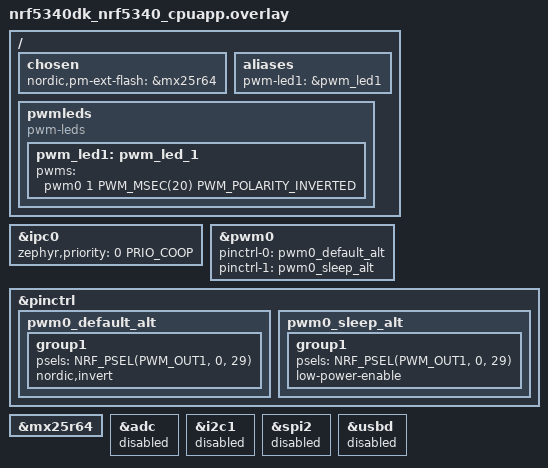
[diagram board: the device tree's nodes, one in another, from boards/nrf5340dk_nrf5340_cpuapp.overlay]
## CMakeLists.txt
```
#
#    Copyright (c) 2020 Project CHIP Authors
#
#    Licensed under the Apache License, Version 2.0 (the "License");
#    you may not use this file except in compliance with the License.
#    You may obtain a copy of the License at
#
#        http://www.apache.org/licenses/LICENSE-2.0
#
#    Unless required by applicable law or agreed to in writing, software
#    distributed under the License is distributed on an "AS IS" BASIS,
#    WITHOUT WARRANTIES OR CONDITIONS OF ANY KIND, either express or implied.
#    See the License for the specific language governing permissions and
#    limitations under the License.
#
cmake_minimum_required(VERSION 3.20)

get_filename_component(CHIP_ROOT ${CMAKE_CURRENT_SOURCE_DIR}/third_party/connectedhomeip REALPATH)
get_filename_component(NRFCONNECT_COMMON ${CHIP_ROOT}/examples/platform/nrfconnect REALPATH)
get_filename_component(LIGHTING_COMMON ${CHIP_ROOT}/examples/lighting-app/lighting-common REALPATH)
get_filename_component(GEN_DIR ${CHIP_ROOT}/zzz_generated/ REALPATH)

include(${CHIP_ROOT}/config/nrfconnect/app/check-nrfconnect-version.cmake)

list(APPEND ZEPHYR_EXTRA_MODULES ${CHIP_ROOT}/config/nrfconnect/chip-module)
find_package(Zephyr HINTS $ENV{ZEPHYR_BASE})

project(chip-nrfconnect-lighting-example)

include(${CHIP_ROOT}/config/nrfconnect/app/check-sysbuild-use.cmake)
include(${CHIP_ROOT}/config/nrfconnect/app/enable-gnu-std.cmake)
include(${CHIP_ROOT}/config/nrfconnect/app/flashing.cmake)
include(${CHIP_ROOT}/src/app/chip_data_model.cmake)

# -Wmaybe-uninitialized has too many false positives, including on std::optional
# and chip::Optional.  Make it nonfatal.
#
# See https://gcc.gnu.org/bugzilla/show_bug.cgi?id=80635
target_compile_options(app PRIVATE -Werror -Wno-error=maybe-uninitialized)

target_include_directories(app PRIVATE
                           main/include
                           ${LIGHTING_COMMON}
                           ${GEN_DIR}
                           ${GEN_DIR}/app-common
                           ${GEN_DIR}/lighting-app
                           ${NRFCONNECT_COMMON}/util/include
                           ${NRFCONNECT_COMMON}/app/include)

target_sources(app PRIVATE
               main/AppTask.cpp
               main/main.cpp
               main/ZclCallbacks.cpp
               ${CHIP_ROOT}/src/app/persistence/DeferredAttributePersistenceProvider.cpp
               ${NRFCONNECT_COMMON}/util/LEDWidget.cpp
               ${NRFCONNECT_COMMON}/util/PWMDevice.cpp)

chip_configure_data_model(app
    ZAP_FILE ${CMAKE_CURRENT_SOURCE_DIR}/../lighting-common/lighting-app.zap
)

if(CONFIG_CHIP_OTA_REQUESTOR OR CONFIG_MCUMGR_TRANSPORT_BT)
    target_sources(app PRIVATE ${NRFCONNECT_COMMON}/util/OTAUtil.cpp)
endif()

if(CONFIG_MCUMGR_TRANSPORT_BT)
    zephyr_library_link_libraries(MCUBOOT_BOOTUTIL)
    target_sources(app PRIVATE ${NRFCONNECT_COMMON}/util/DFUOverSMP.cpp)
endif()

if (CONFIG_SHELL AND BOARD STREQUAL "nrf52840dongle_nrf52840")
  target_sources(app PRIVATE ${NRFCONNECT_COMMON}/util/DFUTrigger.cpp)
endif()

if (CONFIG_CHIP_PW_RPC)

# Make all targets created below depend on zephyr_interface to inherit MCU-related compilation flags
link_libraries($<BUILD_INTERFACE:zephyr_interface>)

set(PIGWEED_ROOT "${CHIP_ROOT}/third_party/pigweed/repo")
include(${PIGWEED_ROOT}/pw_build/pigweed.cmake)
include(${PIGWEED_ROOT}/pw_protobuf_compiler/proto.cmake)

pw_set_module_config(pw_rpc_CONFIG pw_rpc.disable_global_mutex_config)
pw_set_backend(pw_log pw_log_basic)
pw_set_backend(pw_assert.check pw_assert_log.check_backend)
pw_set_backend(pw_assert.assert pw_assert.assert_compatibility_backend)
pw_set_backend(pw_sys_io pw_sys_io.nrfconnect)
set(dir_pw_third_party_nanopb "${CHIP_ROOT}/third_party/nanopb/repo" CACHE STRING "" FORCE)

add_subdirectory(third_party/connectedhomeip/examples/platform/nrfconnect/pw_sys_io)
add_subdirectory(third_party/connectedhomeip/third_party/nanopb/repo)
add_subdirectory(third_party/connectedhomeip/third_party/pigweed/repo)

pw_proto_library(attributes_service
  SOURCES
    ${CHIP_ROOT}/examples/common/pigweed/protos/attributes_service.proto
  INPUTS
    ${CHIP_ROOT}/examples/common/pigweed/protos/attributes_service.options
  PREFIX
    attributes_service
  STRIP_PREFIX
    ${CHIP_ROOT}/examples/common/pigweed/protos
  DEPS
    pw_protobuf.common_proto
)

pw_proto_library(button_service
  SOURCES
    ${CHIP_ROOT}/examples/common/pigweed/protos/button_service.proto
  PREFIX
    button_service
  STRIP_PREFIX
    ${CHIP_ROOT}/examples/common/pigweed/protos
  DEPS
    pw_protobuf.common_proto
)

pw_proto_library(descriptor_service
  SOURCES
    ${CHIP_ROOT}/examples/common/pigweed/protos/descriptor_service.proto
  PREFIX
    descriptor_service
  STRIP_PREFIX
    ${CHIP_ROOT}/examples/common/pigweed/protos
  DEPS
    pw_protobuf.common_proto
)

pw_proto_library(device_service
  SOURCES
    ${CHIP_ROOT}/examples/common/pigweed/protos/device_service.proto
  INPUTS
    ${CHIP_ROOT}/examples/common/pigweed/protos/device_service.options
  PREFIX
    device_service
  STRIP_PREFIX
    ${CHIP_ROOT}/examples/common/pigweed/protos
  DEPS
    pw_protobuf.common_proto
)

pw_proto_library(lighting_service
  SOURCES
    ${CHIP_ROOT}/examples/common/pigweed/protos/lighting_service.proto
  STRIP_PREFIX
    ${CHIP_ROOT}/examples/common/pigweed/protos
  PREFIX
    lighting_service
  DEPS
    pw_protobuf.common_proto
)

pw_proto_library(ot_cli_service
  SOURCES
    ${CHIP_ROOT}/examples/common/pigweed/protos/ot_cli_service.proto
  INPUTS
    ${CHIP_ROOT}/examples/common/pigweed/protos/ot_cli_service.options
  STRIP_PREFIX
    ${CHIP_ROOT}/examples/common/pigweed/protos
  PREFIX
    ot_cli_service
  DEPS
    pw_protobuf.common_proto
)

pw_proto_library(thread_service
  SOURCES
    ${CHIP_ROOT}/examples/common/pigweed/protos/thread_service.proto
  INPUTS
    ${CHIP_ROOT}/examples/common/pigweed/protos/thread_service.options
  STRIP_PREFIX
    ${CHIP_ROOT}/examples/common/pigweed/protos
  PREFIX
    thread_service
  DEPS
    pw_protobuf.common_proto
)

target_sources(app PRIVATE
  ../../common/pigweed/RpcService.cpp
  ../../common/pigweed/nrfconnect/PigweedLoggerMutex.cpp
  ${NRFCONNECT_COMMON}/Rpc.cpp
  ${NRFCONNECT_COMMON}/util/PigweedLogger.cpp
)

target_include_directories(app PRIVATE
  ${CHIP_ROOT}/src/lib/support
  ${CHIP_ROOT}/src/system
  ${NRFCONNECT_COMMON}
  ../../common
  ../../common/pigweed
  ../../common/pigweed/nrfconnect)

target_compile_options(app PRIVATE
                       "-DPW_RPC_ATTRIBUTE_SERVICE=1"
                       "-DPW_RPC_BUTTON_SERVICE=1"
                       "-DPW_RPC_DESCRIPTOR_SERVICE=1"
                       "-DPW_RPC_DEVICE_SERVICE=1"
                       "-DPW_RPC_LIGHTING_SERVICE=1"
                       "-DPW_RPC_THREAD_SERVICE=1"
                       )

target_link_libraries(app PRIVATE
  attributes_service.nanopb_rpc
  button_service.nanopb_rpc
  descriptor_service.nanopb_rpc
  device_service.nanopb_rpc
  lighting_service.nanopb_rpc
  thread_service.nanopb_rpc
  pw_checksum
  pw_hdlc
  pw_log
  pw_rpc.server
  pw_sys_io
)

endif(CONFIG_CHIP_PW_RPC)
```

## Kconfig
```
#
#    Copyright (c) 2022 Project CHIP Authors
#
#    Licensed under the Apache License, Version 2.0 (the "License");
#    you may not use this file except in compliance with the License.
#    You may obtain a copy of the License at
#
#        http://www.apache.org/licenses/LICENSE-2.0
#
#    Unless required by applicable law or agreed to in writing, software
#    distributed under the License is distributed on an "AS IS" BASIS,
#    WITHOUT WARRANTIES OR CONDITIONS OF ANY KIND, either express or implied.
#    See the License for the specific language governing permissions and
#    limitations under the License.
#

mainmenu "Matter nRF Connect Light Bulb Example Application"

# Sample configuration used for Thread networking
if OPENTHREAD

choice OPENTHREAD_NORDIC_LIBRARY_CONFIGURATION
	default OPENTHREAD_NORDIC_LIBRARY_FTD
endchoice

choice OPENTHREAD_DEVICE_TYPE
	default OPENTHREAD_FTD
endchoice

endif # OPENTHREAD

config CHIP_WIFI
	default y if SHIELD_NRF7002EB2

rsource "../../../config/nrfconnect/chip-module/Kconfig.features"
rsource "../../../config/nrfconnect/chip-module/Kconfig.defaults"
source "Kconfig.zephyr"
```

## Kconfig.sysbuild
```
#
#    Copyright (c) 2022-2026 Project CHIP Authors
#
#    Licensed under the Apache License, Version 2.0 (the "License");
#    you may not use this file except in compliance with the License.
#    You may obtain a copy of the License at
#
#        http://www.apache.org/licenses/LICENSE-2.0
#
#    Unless required by applicable law or agreed to in writing, software
#    distributed under the License is distributed on an "AS IS" BASIS,
#    WITHOUT WARRANTIES OR CONDITIONS OF ANY KIND, either express or implied.
#    See the License for the specific language governing permissions and
#    limitations under the License.
#

config MATTER_ADD_ON
	default y

#### Radio core selection
config NRF_DEFAULT_IPC_RADIO
	default y

# Enable IEEE802.15.4 serialization to network core
# This config automatically pulls in the `overlay-802154.conf` in the ipc_radio image
config NETCORE_IPC_RADIO_IEEE802154
	default y if SOC_SERIES_NRF53 && !WIFI_NRF70

# Enable Bluetooth serialization to network core
# This config automatically pulls in the `overlay-bt_hci_ipc.conf` in the ipc_radio image
config NETCORE_IPC_RADIO_BT_HCI_IPC
	default y if SOC_SERIES_NRF53

#### Bootloader
choice BOOTLOADER
	default BOOTLOADER_MCUBOOT if !BOARD_NRF21540DK
endchoice

if BOOTLOADER_MCUBOOT

#### DFU multi-image support
config DFU_MULTI_IMAGE_PACKAGE_BUILD
	default y

config DFU_MULTI_IMAGE_PACKAGE_APP
	default y

#### DFU network core configuration
if SOC_SERIES_NRF53

choice MCUBOOT_MODE
	default MCUBOOT_MODE_OVERWRITE_ONLY
endchoice

choice BOOT_SIGNATURE_TYPE
	default BOOT_SIGNATURE_TYPE_RSA
endchoice

config SECURE_BOOT_NETCORE
	default y

config NETCORE_APP_UPDATE
	default y

config DFU_MULTI_IMAGE_PACKAGE_NET
	default y

endif # SOC_SERIES_NRF53
endif # BOOTLOADER_MCUBOOT

#### Enable generating factory data
config MATTER_ADD_ON_FACTORY_DATA_GENERATE
	default y if !BOARD_NRF21540DK

source "share/sysbuild/Kconfig"
```

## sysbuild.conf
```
#
#    Copyright (c) 2026 Project CHIP Authors
#
#    Licensed under the Apache License, Version 2.0 (the "License");
#    you may not use this file except in compliance with the License.
#    You may obtain a copy of the License at
#
#        http://www.apache.org/licenses/LICENSE-2.0
#
#    Unless required by applicable law or agreed to in writing, software
#    distributed under the License is distributed on an "AS IS" BASIS,
#    WITHOUT WARRANTIES OR CONDITIONS OF ANY KIND, either express or implied.
#    See the License for the specific language governing permissions and
#    limitations under the License.
#

SB_CONFIG_MATTER_ADD_ON=y
SB_CONFIG_MATTER_ROOT_PATH="${ZEPHYR_NCS_MATTER_MODULE_DIR}/../../.."
```

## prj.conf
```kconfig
#
#    Copyright (c) 2022-2026 Project CHIP Authors
#
#    Licensed under the Apache License, Version 2.0 (the "License");
#    you may not use this file except in compliance with the License.
#    You may obtain a copy of the License at
#
#        http://www.apache.org/licenses/LICENSE-2.0
#
#    Unless required by applicable law or agreed to in writing, software
#    distributed under the License is distributed on an "AS IS" BASIS,
#    WITHOUT WARRANTIES OR CONDITIONS OF ANY KIND, either express or implied.
#    See the License for the specific language governing permissions and
#    limitations under the License.
#

# Enable CHIP
CONFIG_CHIP=y
CONFIG_CHIP_PROJECT_CONFIG="src/chip_project_config.h"
CONFIG_CHIP_DEVICE_PRODUCT_NAME="Matter Light Bulb"

# Configure ZAP file name
CONFIG_MATTER_ZAP_FILE_PATH="${APPLICATION_CONFIG_DIR}/src/default_zap/light_bulb.zap"

# 32773 == 0x8005 (example lighting-app)
CONFIG_CHIP_DEVICE_PRODUCT_ID=32773
CONFIG_STD_CPP17=y

# Enable Matter pairing automatically on application start.
CONFIG_CHIP_ENABLE_PAIRING_AUTOSTART=y

# Enable Matter extended announcement and increase duration to 1 hour.
CONFIG_CHIP_BLE_EXT_ADVERTISING=y
CONFIG_CHIP_BLE_ADVERTISING_DURATION=60

# Add support for LEDs and buttons on Nordic development kits
CONFIG_DK_LIBRARY=y
CONFIG_PWM=y

# Bluetooth Low Energy configuration
CONFIG_BT_DEVICE_NAME="MatterLight"

# Other settings
CONFIG_THREAD_NAME=y
CONFIG_MPU_STACK_GUARD=y
CONFIG_RESET_ON_FATAL_ERROR=n
CONFIG_CHIP_LIB_SHELL=y
CONFIG_MATTER_TEST_SHELL=y

# Reduce application size
CONFIG_USE_SEGGER_RTT=n

# Enable Factory Data feature
CONFIG_CHIP_FACTORY_DATA=y
CONFIG_CHIP_FACTORY_DATA_BUILD=y
```

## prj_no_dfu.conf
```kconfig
#
#    Copyright (c) 2022 Project CHIP Authors
#
#    Licensed under the Apache License, Version 2.0 (the "License");
#    you may not use this file except in compliance with the License.
#    You may obtain a copy of the License at
#
#        http://www.apache.org/licenses/LICENSE-2.0
#
#    Unless required by applicable law or agreed to in writing, software
#    distributed under the License is distributed on an "AS IS" BASIS,
#    WITHOUT WARRANTIES OR CONDITIONS OF ANY KIND, either express or implied.
#    See the License for the specific language governing permissions and
#    limitations under the License.
#

# This sample uses Kconfig.defaults to set options common for all
# samples. This file should contain only options specific for this sample
# or overrides of default values.

# Enable CHIP
CONFIG_CHIP=y
CONFIG_CHIP_PROJECT_CONFIG="main/include/CHIPProjectConfig.h"
# 32773 == 0x8005 (example lighting-app)
CONFIG_CHIP_DEVICE_PRODUCT_ID=32773
CONFIG_STD_CPP17=y

# Enable CHIP pairing automatically on application start.
CONFIG_CHIP_ENABLE_PAIRING_AUTOSTART=y

# Add support for LEDs and buttons on Nordic development kits
CONFIG_DK_LIBRARY=y
CONFIG_PWM=y

# General networking settings
CONFIG_NET_IF_MCAST_IPV6_ADDR_COUNT=14

# Bluetooth Low Energy configuration
CONFIG_BT_DEVICE_NAME="MatterLight"

# Other settings
CONFIG_THREAD_NAME=y
CONFIG_MPU_STACK_GUARD=y
CONFIG_RESET_ON_FATAL_ERROR=n

# Reduce application size
CONFIG_USE_SEGGER_RTT=n

# Stack size settings
CONFIG_IEEE802154_NRF5_RX_STACK_SIZE=1024

# Disable Matter OTA DFU
CONFIG_CHIP_OTA_REQUESTOR=n

# Disable QSPI NOR
CONFIG_CHIP_QSPI_NOR=n
```

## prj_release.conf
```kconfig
#
#    Copyright (c) 2022-2026 Project CHIP Authors
#
#    Licensed under the Apache License, Version 2.0 (the "License");
#    you may not use this file except in compliance with the License.
#    You may obtain a copy of the License at
#
#        http://www.apache.org/licenses/LICENSE-2.0
#
#    Unless required by applicable law or agreed to in writing, software
#    distributed under the License is distributed on an "AS IS" BASIS,
#    WITHOUT WARRANTIES OR CONDITIONS OF ANY KIND, either express or implied.
#    See the License for the specific language governing permissions and
#    limitations under the License.
#

# Enable CHIP
CONFIG_CHIP=y
CONFIG_CHIP_PROJECT_CONFIG="src/chip_project_config.h"
CONFIG_CHIP_DEVICE_PRODUCT_NAME="Matter Light Bulb"

# Configure ZAP file name
CONFIG_MATTER_ZAP_FILE_PATH="${APPLICATION_CONFIG_DIR}/src/default_zap/light_bulb.zap"

# 32773 == 0x8005 (example lighting-app)
CONFIG_CHIP_DEVICE_PRODUCT_ID=32773
CONFIG_STD_CPP17=y

# Enable Matter pairing automatically on application start.
CONFIG_CHIP_ENABLE_PAIRING_AUTOSTART=y

# Enable Matter extended announcement and increase duration to 1 hour.
CONFIG_CHIP_BLE_EXT_ADVERTISING=y
CONFIG_CHIP_BLE_ADVERTISING_DURATION=60

# Add support for LEDs and buttons on Nordic development kits
CONFIG_DK_LIBRARY=y
CONFIG_PWM=y

# Bluetooth Low Energy configuration
CONFIG_BT_DEVICE_NAME="MatterLight"

# Enable system reset on fatal error
CONFIG_RESET_ON_FATAL_ERROR=y

# Disable all debug features
CONFIG_USE_SEGGER_RTT=n
CONFIG_SHELL=n
CONFIG_OPENTHREAD_SHELL=n
CONFIG_CONSOLE=n
CONFIG_UART_CONSOLE=n
CONFIG_SERIAL=n
CONFIG_LOG=n
CONFIG_LOG_MODE_MINIMAL=n
CONFIG_ASSERT_VERBOSE=n
CONFIG_ASSERT_NO_FILE_INFO=y
CONFIG_PRINTK=n
CONFIG_PRINTK_SYNC=n
CONFIG_THREAD_NAME=n
CONFIG_BOOT_BANNER=n

# Enable Factory Data feature
CONFIG_CHIP_FACTORY_DATA=y
CONFIG_CHIP_FACTORY_DATA_BUILD=y

# Enable Watchdog
CONFIG_MATTER_WATCHDOG=y

# Enable LTO to decrease the flash usage.
CONFIG_LTO=y
CONFIG_ISR_TABLES_LOCAL_DECLARATION=y
```

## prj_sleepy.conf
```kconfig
#
#    Copyright (c) 2022 Project CHIP Authors
#
#    Licensed under the Apache License, Version 2.0 (the "License");
#    you may not use this file except in compliance with the License.
#    You may obtain a copy of the License at
#
#        http://www.apache.org/licenses/LICENSE-2.0
#
#    Unless required by applicable law or agreed to in writing, software
#    distributed under the License is distributed on an "AS IS" BASIS,
#    WITHOUT WARRANTIES OR CONDITIONS OF ANY KIND, either express or implied.
#    See the License for the specific language governing permissions and
#    limitations under the License.
#

CONFIG_CHIP=y
CONFIG_STD_CPP14=y

# This sample uses Kconfig.defaults to set options common for all
# samples. This file should contain only options specific for this sample
# or overrides of default values.

# Add support for LEDs and buttons on Nordic development kits
CONFIG_DK_LIBRARY=y
CONFIG_PWM=y

# OpenThread configs
CONFIG_OPENTHREAD_NORDIC_LIBRARY_MTD=y
CONFIG_OPENTHREAD_MTD=y
CONFIG_OPENTHREAD_FTD=n
CONFIG_CHIP_ENABLE_SLEEPY_END_DEVICE_SUPPORT=y

# SED configuration
CONFIG_CHIP_THREAD_SSED=y # CSL
CONFIG_CHIP_SED_IDLE_INTERVAL=5000
CONFIG_CHIP_SED_ACTIVE_INTERVAL=500

# Bluetooth overrides
CONFIG_BT_DEVICE_NAME="MatterLight"

# Additional configs for debbugging experience.
CONFIG_RESET_ON_FATAL_ERROR=n

# CHIP configuration
CONFIG_CHIP_PROJECT_CONFIG="main/include/CHIPProjectConfig.h"
# 32773 == 0x8005 (example lighting-app)
CONFIG_CHIP_DEVICE_PRODUCT_ID=32773

# Suspend devices when the CPU goes into sleep
CONFIG_PM_DEVICE=y

# Enable CHIP pairing automatically on application start.
CONFIG_CHIP_ENABLE_PAIRING_AUTOSTART=y
```

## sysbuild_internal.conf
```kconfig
#
#    Copyright (c) 2024-2026 Project CHIP Authors
#
#    Licensed under the Apache License, Version 2.0 (the "License");
#    you may not use this file except in compliance with the License.
#    You may obtain a copy of the License at
#
#        http://www.apache.org/licenses/LICENSE-2.0
#
#    Unless required by applicable law or agreed to in writing, software
#    distributed under the License is distributed on an "AS IS" BASIS,
#    WITHOUT WARRANTIES OR CONDITIONS OF ANY KIND, either express or implied.
#    See the License for the specific language governing permissions and
#    limitations under the License.
#

# Enable the DFU image compression.
SB_CONFIG_MCUBOOT_MODE_OVERWRITE_ONLY=y
SB_CONFIG_MCUBOOT_COMPRESSED_IMAGE_SUPPORT=y
```

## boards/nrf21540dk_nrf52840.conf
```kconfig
#
# Copyright (c) 2022 Nordic Semiconductor ASA
#
# SPDX-License-Identifier: LicenseRef-Nordic-5-Clause
#

# This sample uses Kconfig.defaults to set options common for all
# samples. This file should contain only options specific for this sample
# or overrides of default values.

# Other settings
CONFIG_THREAD_NAME=y
CONFIG_MPU_STACK_GUARD=y
CONFIG_RESET_ON_FATAL_ERROR=n
CONFIG_CHIP_LIB_SHELL=y

# Disable Matter OTA DFU
CONFIG_CHIP_OTA_REQUESTOR=n

# Disable Factory data feature since the board doesn't have external flash memory.
CONFIG_CHIP_FACTORY_DATA=n
CONFIG_CHIP_FACTORY_DATA_BUILD=n
CONFIG_CHIP_FACTORY_DATA_NONE=y
```

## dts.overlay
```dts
/*
 *    Copyright (c) 2020 Project CHIP Authors
 *
 *    Licensed under the Apache License, Version 2.0 (the "License");
 *    you may not use this file except in compliance with the License.
 *    You may obtain a copy of the License at
 *
 *        http://www.apache.org/licenses/LICENSE-2.0
 *
 *    Unless required by applicable law or agreed to in writing, software
 *    distributed under the License is distributed on an "AS IS" BASIS,
 *    WITHOUT WARRANTIES OR CONDITIONS OF ANY KIND, either express or implied.
 *    See the License for the specific language governing permissions and
 *    limitations under the License.
 */

/ {

	/*
	* In some default configurations within the nRF Connect SDK,
	* e.g. on nRF52840, the chosen zephyr,entropy node is &cryptocell.
	* This devicetree overlay ensures that default is overridden wherever it
	* is set, as this application uses the RNG node for entropy exclusively.
	*/

	chosen {
		zephyr,entropy = &rng;
	};

	/*
	* By default, PWM module is only configured for led0 (LED1 on the board).
	* The lighting-app, however, uses LED2 to show the state of the lighting,
	* including its brightness level.
	*/
	aliases {
		pwm-led1 = &pwm_led1;
	};

	pwmleds {
		pwm_led1: pwm_led_1 {
			pwms = < &pwm0 0xe >;
		};
	};

};

&pwm0 {
	ch1-pin = < 0xe >;
	ch1-inverted;
};
```

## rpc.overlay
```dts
#
#    Copyright (c) 2020 Project CHIP Authors
#
#    Licensed under the Apache License, Version 2.0 (the "License");
#    you may not use this file except in compliance with the License.
#    You may obtain a copy of the License at
#
#        http://www.apache.org/licenses/LICENSE-2.0
#
#    Unless required by applicable law or agreed to in writing, software
#    distributed under the License is distributed on an "AS IS" BASIS,
#    WITHOUT WARRANTIES OR CONDITIONS OF ANY KIND, either express or implied.
#    See the License for the specific language governing permissions and
#    limitations under the License.
#

# This file should be used as a configuration overlay to build Pigweed RPCs to
# lighting-app.

# Enable Pigweed RPC
CONFIG_CHIP_PW_RPC=y

# Add support for C++17 to build Pigweed components
CONFIG_STD_CPP14=n
CONFIG_STD_CPP17=y

# Add support for Zephyr console component to use it for Pigweed console purposes
CONFIG_CONSOLE_SUBSYS=y
CONFIG_CONSOLE_GETCHAR=y
CONFIG_CONSOLE_PUTCHAR_BUFSIZE=256

# Disable features which may interfere with Pigweed HDLC transport
CONFIG_MATTER_TEST_SHELL=n
CONFIG_CHIP_LIB_SHELL=n
CONFIG_SHELL=n
CONFIG_OPENTHREAD_SHELL=n
CONFIG_BOOT_BANNER=n

# Configure Zephyr logger with defaults backends disabled as the app provides its own,
# based on Pigweed HDLC.
CONFIG_LOG=y
CONFIG_LOG_MODE_MINIMAL=n
CONFIG_LOG_MODE_IMMEDIATE=y
CONFIG_LOG_BACKEND_UART=n
CONFIG_LOG_BACKEND_RTT=n
CONFIG_LOG_OUTPUT=y

# Increase zephyr tty rx buffer
CONFIG_CONSOLE_GETCHAR_BUFSIZE=128

# Increase thread stack sizes
CONFIG_BT_RX_STACK_SIZE=4096
CONFIG_MAIN_STACK_SIZE=8092
CONFIG_SYSTEM_WORKQUEUE_STACK_SIZE=2048
```

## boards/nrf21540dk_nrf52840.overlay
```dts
/*
 * Copyright (c) 2021-2022 Nordic Semiconductor ASA
 *
 * SPDX-License-Identifier: LicenseRef-Nordic-5-Clause
 */

#include <nrf52840_partitions.dtsi>

/ {
	/*
	 * By default, PWM module is only configured for led0 (LED1 on the board).
	 * The light bulb app, however, uses LED2 to show the state of the lighting,
	 * including its brightness level.
	 */
	aliases {
		pwm-led1 = &pwm_led1;
	};

	pwmleds {
		pwm_led1: pwm_led_1 {
			pwms = <&pwm0 1 PWM_MSEC(20) PWM_POLARITY_INVERTED>;
		};
	};
};

&pwm0 {
	pinctrl-0 = <&pwm0_default_alt>;
	pinctrl-1 = <&pwm0_sleep_alt>;
	pinctrl-names = "default", "sleep";
};

&pinctrl {
	pwm0_default_alt: pwm0_default_alt {
		group1 {
			psels = <NRF_PSEL(PWM_OUT1, 0, 14)>;
			nordic,invert;
		};
	};

	pwm0_sleep_alt: pwm0_sleep_alt {
		group1 {
			psels = <NRF_PSEL(PWM_OUT1, 0, 14)>;
			low-power-enable;
		};
	};
};

/* Disable unused peripherals to reduce power consumption */
&adc {
	status = "disabled";
};

&uart1 {
	status = "disabled";
};

&i2c0 {
	status = "disabled";
};

&spi1 {
	status = "disabled";
};

&spi3 {
	status = "disabled";
};

&usbd {
	status = "disabled";
};
```

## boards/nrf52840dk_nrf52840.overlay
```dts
/*
 * SPDX-FileCopyrightText: 2021 Project CHIP Authors
 *
 * SPDX-License-Identifier: Apache-2.0
 */

/ {
	chosen {
		nordic,pm-ext-flash = &mx25r64;
	};

	/*
	* In some default configurations within the nRF Connect SDK,
	* e.g. on nRF52840, the chosen zephyr,entropy node is &cryptocell.
	* This devicetree overlay ensures that default is overridden wherever it
	* is set, as this application uses the RNG node for entropy exclusively.
	*/

	chosen {
		zephyr,entropy = &rng;
	};

	/*
	* By default, PWM module is only configured for led0 (LED1 on the board).
	* The lighting-app, however, uses LED2 to show the state of the lighting,
	* including its brightness level.
	*/
	aliases {
		pwm-led1 = &pwm_led1;
	};

	pwmleds {
		pwm_led1: pwm_led_1 {
			pwms = <&pwm0 1 PWM_MSEC(20) PWM_POLARITY_INVERTED>;
		};
	};

};

&pwm0 {
	pinctrl-0 = <&pwm0_default_alt>;
	pinctrl-1 = <&pwm0_sleep_alt>;
	pinctrl-names = "default", "sleep";
};

&pinctrl {
	pwm0_default_alt: pwm0_default_alt {
		group1 {
			psels = <NRF_PSEL(PWM_OUT1, 0, 14)>;
			nordic,invert;
		};
	};

	pwm0_sleep_alt: pwm0_sleep_alt {
		group1 {
			psels = <NRF_PSEL(PWM_OUT1, 0, 14)>;
			low-power-enable;
		};
	};

};
```

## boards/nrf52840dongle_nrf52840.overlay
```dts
/*
 *    Copyright (c) 2021 Project CHIP Authors
 *
 *    Licensed under the Apache License, Version 2.0 (the "License");
 *    you may not use this file except in compliance with the License.
 *    You may obtain a copy of the License at
 *
 *        http: //www.apache.org/licenses/LICENSE-2.0
 *
 *    Unless required by applicable law or agreed to in writing, software
 *    distributed under the License is distributed on an "AS IS" BASIS,
 *    WITHOUT WARRANTIES OR CONDITIONS OF ANY KIND, either express or implied.
 *    See the License for the specific language governing permissions and
 *    limitations under the License.
 */

 / {
 	chosen {
 		zephyr,console = &board_cdc_acm_uart;
	};
};

&uart0 {
	status = "okay";
	hw-flow-control;
};
```

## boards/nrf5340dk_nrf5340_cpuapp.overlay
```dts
/*
 * Copyright (c) 2021-2022 Nordic Semiconductor ASA
 *
 * SPDX-License-Identifier: LicenseRef-Nordic-5-Clause
 */

#include <nrf5340_cpuapp_partitions.dtsi>
#include <zephyr/dt-bindings/ipc_service/static_vrings.h>

/ {
	chosen {
		nordic,pm-ext-flash = &mx25r64;
	};

	/*
	 * By default, PWM module is only configured for led0 (LED1 on the board).
	 * The light bulb app, however, uses LED2 to show the state of the lighting,
	 * including its brightness level.
	 */
	aliases {
		pwm-led1 = &pwm_led1;
	};

	pwmleds {
		compatible = "pwm-leds";

		pwm_led1: pwm_led_1 {
			pwms = <&pwm0 1 PWM_MSEC(20) PWM_POLARITY_INVERTED>;
		};
	};
};

/* Set IPC thread priority to the highest value to not collide with other threads. */
&ipc0 {
	zephyr,priority = <0 PRIO_COOP>;
};

&pwm0 {
	pinctrl-0 = <&pwm0_default_alt>;
	pinctrl-1 = <&pwm0_sleep_alt>;
	pinctrl-names = "default", "sleep";
};

&pinctrl {
	pwm0_default_alt: pwm0_default_alt {
		group1 {
			psels = <NRF_PSEL(PWM_OUT1, 0, 29)>;
			nordic,invert;
		};
	};

	pwm0_sleep_alt: pwm0_sleep_alt {
		group1 {
			psels = <NRF_PSEL(PWM_OUT1, 0, 29)>;
			low-power-enable;
		};
	};
};

&mx25r64 {
	status = "okay";
};

/* Disable unused peripherals to reduce power consumption */
&adc {
	status = "disabled";
};

&i2c1 {
	status = "disabled";
};

&spi2 {
	status = "disabled";
};

&usbd {
	status = "disabled";
};
```

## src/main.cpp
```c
/*
 *
 *    Copyright (c) 2020 Project CHIP Authors
 *    All rights reserved.
 *
 *    Licensed under the Apache License, Version 2.0 (the "License");
 *    you may not use this file except in compliance with the License.
 *    You may obtain a copy of the License at
 *
 *        http://www.apache.org/licenses/LICENSE-2.0
 *
 *    Unless required by applicable law or agreed to in writing, software
 *    distributed under the License is distributed on an "AS IS" BASIS,
 *    WITHOUT WARRANTIES OR CONDITIONS OF ANY KIND, either express or implied.
 *    See the License for the specific language governing permissions and
 *    limitations under the License.
 */

#include "app_task.h"

#include <zephyr/logging/log.h>

LOG_MODULE_REGISTER(app, CONFIG_CHIP_APP_LOG_LEVEL);

int main()
{
    CHIP_ERROR err = AppTask::Instance().StartApp();

    LOG_ERR("Exited with code %" CHIP_ERROR_FORMAT, err.Format());
    return err == CHIP_NO_ERROR ? EXIT_SUCCESS : EXIT_FAILURE;
}
```

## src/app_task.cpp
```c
/*
 *
 *    Copyright (c) 2020-2026 Project CHIP Authors
 *    All rights reserved.
 *
 *    Licensed under the Apache License, Version 2.0 (the "License");
 *    you may not use this file except in compliance with the License.
 *    You may obtain a copy of the License at
 *
 *        http://www.apache.org/licenses/LICENSE-2.0
 *
 *    Unless required by applicable law or agreed to in writing, software
 *    distributed under the License is distributed on an "AS IS" BASIS,
 *    WITHOUT WARRANTIES OR CONDITIONS OF ANY KIND, either express or implied.
 *    See the License for the specific language governing permissions and
 *    limitations under the License.
 */

#include "app_task.h"

#include "app/matter_init.h"
#include "app/task_executor.h"

#if defined(CONFIG_PWM)
#include "pwm/pwm_device.h"
#endif

#include "clusters/identify.h"

#include <app-common/zap-generated/attributes/Accessors.h>
#include <app/persistence/AttributePersistenceProviderInstance.h>
#include <app/persistence/DefaultAttributePersistenceProvider.h>
#include <app/persistence/DeferredAttributePersistenceProvider.h>
#include <app/server/Server.h>
#include <setup_payload/OnboardingCodesUtil.h>

#include <zephyr/logging/log.h>

LOG_MODULE_DECLARE(app, CONFIG_CHIP_APP_LOG_LEVEL);

using namespace ::chip;
using namespace ::chip::app;
using namespace ::chip::DeviceLayer;

namespace {
constexpr EndpointId kLightEndpointId = 1;
constexpr uint8_t kDefaultMinLevel    = 0;
constexpr uint8_t kDefaultMaxLevel    = 254;

Nrf::Matter::IdentifyCluster sIdentifyCluster(kLightEndpointId, true, []() {
    Nrf::PostTask([] { Nrf::GetBoard().GetLED(Nrf::DeviceLeds::LED2).Set(false); });
#if defined(CONFIG_PWM)
    Nrf::PostTask([] { AppTask::Instance().GetPWMDevice().ApplyLevel(); });
#endif
});

#if defined(CONFIG_PWM)
const struct pwm_dt_spec sLightPwmDevice = PWM_DT_SPEC_GET(DT_ALIAS(pwm_led1));
#endif

/* Define a custom attribute persister which makes actual write of the CurrentLevel attribute value
 * to the non-volatile storage only when it has remained constant for 5 seconds. This is to reduce
 * the flash wearout when the attribute changes frequently as a result of MoveToLevel command.
 * DeferredAttribute object describes a deferred attribute, but also holds a buffer with a value to
 * be written, so it must live so long as the DeferredAttributePersistenceProvider object.
 */
DeferredAttribute gCurrentLevelPersister(ConcreteAttributePath(kLightEndpointId, Clusters::LevelControl::Id,
                                                               Clusters::LevelControl::Attributes::CurrentLevel::Id));

/* Deferred persistence will be auto-initialized as soon as the default persistence is initialized */
DefaultAttributePersistenceProvider gSimpleAttributePersistence;
DeferredAttributePersistenceProvider gDeferredAttributePersister(gSimpleAttributePersistence,
                                                                 Span<DeferredAttribute>(&gCurrentLevelPersister, 1),
                                                                 System::Clock::Milliseconds32(5000));

#define APPLICATION_BUTTON_MASK DK_BTN2_MSK
} /* namespace */

void AppTask::LightingActionEventHandler(const LightingEvent & event)
{
#if defined(CONFIG_PWM)
    Nrf::PWMDevice::Action_t action = Nrf::PWMDevice::INVALID_ACTION;
    int32_t actor                   = 0;
    if (event.Actor == LightingActor::Button)
    {
        action = Instance().mPWMDevice.IsTurnedOn() ? Nrf::PWMDevice::OFF_ACTION : Nrf::PWMDevice::ON_ACTION;
        actor  = static_cast<int32_t>(event.Actor);
    }

    if (action == Nrf::PWMDevice::INVALID_ACTION || !Instance().mPWMDevice.InitiateAction(action, actor, NULL))
    {
        LOG_INF("An action could not be initiated.");
    }
#else
    Nrf::GetBoard().GetLED(Nrf::DeviceLeds::LED2).Set(!Nrf::GetBoard().GetLED(Nrf::DeviceLeds::LED2).GetState());
#endif
}

void AppTask::ButtonEventHandler(Nrf::ButtonState state, Nrf::ButtonMask hasChanged)
{
    if ((APPLICATION_BUTTON_MASK & hasChanged) & state)
    {
        Nrf::PostTask([] {
            LightingEvent event;
            event.Actor = LightingActor::Button;
            LightingActionEventHandler(event);
        });
    }
}

#if defined(CONFIG_PWM)
void AppTask::ActionInitiated(Nrf::PWMDevice::Action_t action, int32_t actor)
{
    if (action == Nrf::PWMDevice::ON_ACTION)
    {
        LOG_INF("Turn On Action has been initiated");
    }
    else if (action == Nrf::PWMDevice::OFF_ACTION)
    {
        LOG_INF("Turn Off Action has been initiated");
    }
    else if (action == Nrf::PWMDevice::LEVEL_ACTION)
    {
        LOG_INF("Level Action has been initiated");
    }
}

void AppTask::ActionCompleted(Nrf::PWMDevice::Action_t action, int32_t actor)
{
    if (action == Nrf::PWMDevice::ON_ACTION)
    {
        LOG_INF("Turn On Action has been completed");
    }
    else if (action == Nrf::PWMDevice::OFF_ACTION)
    {
        LOG_INF("Turn Off Action has been completed");
    }
    else if (action == Nrf::PWMDevice::LEVEL_ACTION)
    {
        LOG_INF("Level Action has been completed");
    }

    if (actor == static_cast<int32_t>(LightingActor::Button))
    {
        Instance().UpdateClusterState();
    }
}
#endif /* CONFIG_PWM */

void AppTask::UpdateClusterState()
{
    SystemLayer().ScheduleLambda([this] {
#if defined(CONFIG_PWM)
        /* write the new on/off value */
        Protocols::InteractionModel::Status status =
            Clusters::OnOff::Attributes::OnOff::Set(kLightEndpointId, mPWMDevice.IsTurnedOn());
#else
        Protocols::InteractionModel::Status status =
            Clusters::OnOff::Attributes::OnOff::Set(kLightEndpointId, Nrf::GetBoard().GetLED(Nrf::DeviceLeds::LED2).GetState());
#endif
        if (status != Protocols::InteractionModel::Status::Success)
        {
            LOG_ERR("Updating on/off cluster failed: %x", to_underlying(status));
        }

#if defined(CONFIG_PWM)
        /* write the current level */
        status = Clusters::LevelControl::Attributes::CurrentLevel::Set(kLightEndpointId, mPWMDevice.GetLevel());
#else
        /* write the current level */
        if (Nrf::GetBoard().GetLED(Nrf::DeviceLeds::LED2).GetState())
        {
            status = Clusters::LevelControl::Attributes::CurrentLevel::Set(kLightEndpointId, 100);
        }
        else
        {
            status = Clusters::LevelControl::Attributes::CurrentLevel::Set(kLightEndpointId, 0);
        }
#endif

        if (status != Protocols::InteractionModel::Status::Success)
        {
            LOG_ERR("Updating level cluster failed: %x", to_underlying(status));
        }
    });
}

void AppTask::InitPWMDDevice()
{
#if defined(CONFIG_PWM)
    /* Initialize lighting device (PWM) */
    uint8_t minLightLevel = kDefaultMinLevel;
    Clusters::LevelControl::Attributes::MinLevel::Get(kLightEndpointId, &minLightLevel);

    uint8_t maxLightLevel = kDefaultMaxLevel;
    Clusters::LevelControl::Attributes::MaxLevel::Get(kLightEndpointId, &maxLightLevel);

    Clusters::LevelControl::Attributes::CurrentLevel::TypeInfo::Type currentLevel;
    Clusters::LevelControl::Attributes::CurrentLevel::Get(kLightEndpointId, currentLevel);

    int ret = mPWMDevice.Init(&sLightPwmDevice, minLightLevel, maxLightLevel, currentLevel.ValueOr(kDefaultMaxLevel));
    if (ret != 0)
    {
        LOG_ERR("Failed to initialize PWD device.");
    }

    mPWMDevice.SetCallbacks(ActionInitiated, ActionCompleted);
#endif
}

CHIP_ERROR AppTask::Init()
{
    /* Initialize Matter stack */
    ReturnErrorOnFailure(Nrf::Matter::PrepareServer(Nrf::Matter::InitData{ .mPostServerInitClbk = []() {
        app::SetAttributePersistenceProvider(&gDeferredAttributePersister);
        return gSimpleAttributePersistence.Init(Nrf::Matter::GetPersistentStorageDelegate());
    } }));

    if (!Nrf::GetBoard().Init(ButtonEventHandler))
    {
        LOG_ERR("User interface initialization failed.");
        return CHIP_ERROR_INCORRECT_STATE;
    }

    /* Register Matter event handler that controls the connectivity status LED based on the captured Matter network
     * state. */
    ReturnErrorOnFailure(Nrf::Matter::RegisterEventHandler(Nrf::Board::DefaultMatterEventHandler, 0));

    return Nrf::Matter::StartServer();
}

CHIP_ERROR AppTask::StartApp()
{
    ReturnErrorOnFailure(Init());

    while (true)
    {
        Nrf::DispatchNextTask();
    }

    return CHIP_NO_ERROR;
}
```

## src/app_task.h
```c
/*
 *
 *    Copyright (c) 2020-2026 Project CHIP Authors
 *    All rights reserved.
 *
 *    Licensed under the Apache License, Version 2.0 (the "License");
 *    you may not use this file except in compliance with the License.
 *    You may obtain a copy of the License at
 *
 *        http://www.apache.org/licenses/LICENSE-2.0
 *
 *    Unless required by applicable law or agreed to in writing, software
 *    distributed under the License is distributed on an "AS IS" BASIS,
 *    WITHOUT WARRANTIES OR CONDITIONS OF ANY KIND, either express or implied.
 *    See the License for the specific language governing permissions and
 *    limitations under the License.
 */

#pragma once

#include "board/board.h"
#include "pwm/pwm_device.h"

#include <platform/CHIPDeviceLayer.h>

struct k_timer;
struct Identify;

enum class LightingActor : uint8_t
{
    Remote,
    Button
};

struct LightingEvent
{
    uint8_t Action;
    LightingActor Actor;
};

class AppTask
{
public:
    static AppTask & Instance()
    {
        static AppTask sAppTask;
        return sAppTask;
    };

    CHIP_ERROR StartApp();

    void UpdateClusterState();
    void InitPWMDDevice();
    Nrf::PWMDevice & GetPWMDevice() { return mPWMDevice; }

private:
    CHIP_ERROR Init();

    static void LightingActionEventHandler(const LightingEvent & event);
    static void ButtonEventHandler(Nrf::ButtonState state, Nrf::ButtonMask hasChanged);

    static void ActionInitiated(Nrf::PWMDevice::Action_t action, int32_t actor);
    static void ActionCompleted(Nrf::PWMDevice::Action_t action, int32_t actor);

    Nrf::PWMDevice mPWMDevice;
};
```

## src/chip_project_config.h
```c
/*
 * Copyright (c) 2021 Nordic Semiconductor ASA
 *
 * SPDX-License-Identifier: LicenseRef-Nordic-5-Clause
 */

/**
 *    @file
 *          Example project configuration file for CHIP.
 *
 *          This is a place to put application or project-specific overrides
 *          to the default configuration values for general CHIP features.
 *
 */

#pragma once

/* Reduce some flash space when the CONFIG_CHIP_MEMORY_PROFILING is selected */
#ifdef CONFIG_CHIP_MEMORY_PROFILING
#define CHIP_CONFIG_LOG_MODULE_SecureChannel_PROGRESS 0
#define CHIP_CONFIG_LOG_MODULE_FabricProvisioning_PROGRESS 0
#define CHIP_CONFIG_LOG_MODULE_InteractionModel_PROGRESS 0
#define CHIP_CONFIG_LOG_MODULE_InteractionModel_DETAIL 0
#define CHIP_CONFIG_LOG_MODULE_DataManagement_PROGRESS 0
#endif
```

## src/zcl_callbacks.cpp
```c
/*
 *
 *    Copyright (c) 2020 Project CHIP Authors
 *    All rights reserved.
 *
 *    Licensed under the Apache License, Version 2.0 (the "License");
 *    you may not use this file except in compliance with the License.
 *    You may obtain a copy of the License at
 *
 *        http://www.apache.org/licenses/LICENSE-2.0
 *
 *    Unless required by applicable law or agreed to in writing, software
 *    distributed under the License is distributed on an "AS IS" BASIS,
 *    WITHOUT WARRANTIES OR CONDITIONS OF ANY KIND, either express or implied.
 *    See the License for the specific language governing permissions and
 *    limitations under the License.
 */
#include <lib/support/logging/CHIPLogging.h>

#include "app_task.h"

#include <app-common/zap-generated/attributes/Accessors.h>
#include <app-common/zap-generated/ids/Attributes.h>
#include <app-common/zap-generated/ids/Clusters.h>
#include <app/ConcreteAttributePath.h>

using namespace ::chip;
using namespace ::chip::app::Clusters;
using namespace ::chip::app::Clusters::OnOff;

void MatterPostAttributeChangeCallback(const chip::app::ConcreteAttributePath & attributePath, uint8_t type, uint16_t size,
                                       uint8_t * value)
{
    ClusterId clusterId     = attributePath.mClusterId;
    AttributeId attributeId = attributePath.mAttributeId;

    if (clusterId == OnOff::Id && attributeId == OnOff::Attributes::OnOff::Id)
    {
        ChipLogProgress(Zcl, "Cluster OnOff: attribute OnOff set to %" PRIu8 "", *value);

#if defined(CONFIG_PWM)
        AppTask::Instance().GetPWMDevice().InitiateAction(*value ? Nrf::PWMDevice::ON_ACTION : Nrf::PWMDevice::OFF_ACTION,
                                                          static_cast<int32_t>(LightingActor::Remote), value);
#else
        Nrf::GetBoard().GetLED(Nrf::DeviceLeds::LED2).Set(*value);
#endif
    }
    else if (clusterId == LevelControl::Id && attributeId == LevelControl::Attributes::CurrentLevel::Id)
    {
        ChipLogProgress(Zcl, "Cluster LevelControl: attribute CurrentLevel set to %" PRIu8 "", *value);
#if defined(CONFIG_PWM)
        if (AppTask::Instance().GetPWMDevice().IsTurnedOn())
        {
            AppTask::Instance().GetPWMDevice().InitiateAction(Nrf::PWMDevice::LEVEL_ACTION,
                                                              static_cast<int32_t>(LightingActor::Remote), value);
        }
        else
        {
            ChipLogDetail(Zcl, "LED is off. Try to use move-to-level-with-on-off instead of move-to-level");
        }
#endif
    }
}

/** @brief OnOff Cluster Init
 *
 * This function is called when a specific cluster is initialized. It gives the
 * application an opportunity to take care of cluster initialization procedures.
 * It is called exactly once for each endpoint where cluster is present.
 *
 * @param endpoint   Ver.: always
 *
 * TODO Issue #3841
 * emberAfOnOffClusterInitCallback happens before the stack initialize the cluster
 * attributes to the default value.
 * The logic here expects something similar to the deprecated Plugins callback
 * emberAfPluginOnOffClusterServerPostInitCallback.
 *
 */
void emberAfOnOffClusterInitCallback(EndpointId endpoint)
{
    Protocols::InteractionModel::Status status;
    bool storedValue;

    /* Read storedValue on/off value */
    status = Attributes::OnOff::Get(endpoint, &storedValue);

    if (status == Protocols::InteractionModel::Status::Success)
    {
        /* Set actual state to the cluster state that was last persisted */
#if defined(CONFIG_PWM)
        AppTask::Instance().InitPWMDDevice();

        AppTask::Instance().GetPWMDevice().InitiateAction(storedValue ? Nrf::PWMDevice::ON_ACTION : Nrf::PWMDevice::OFF_ACTION,
                                                          static_cast<int32_t>(LightingActor::Remote),
                                                          reinterpret_cast<uint8_t *>(&storedValue));
#else
        Nrf::GetBoard().GetLED(Nrf::DeviceLeds::LED2).Set(storedValue);
#endif
    }

    AppTask::Instance().UpdateClusterState();
}
```
